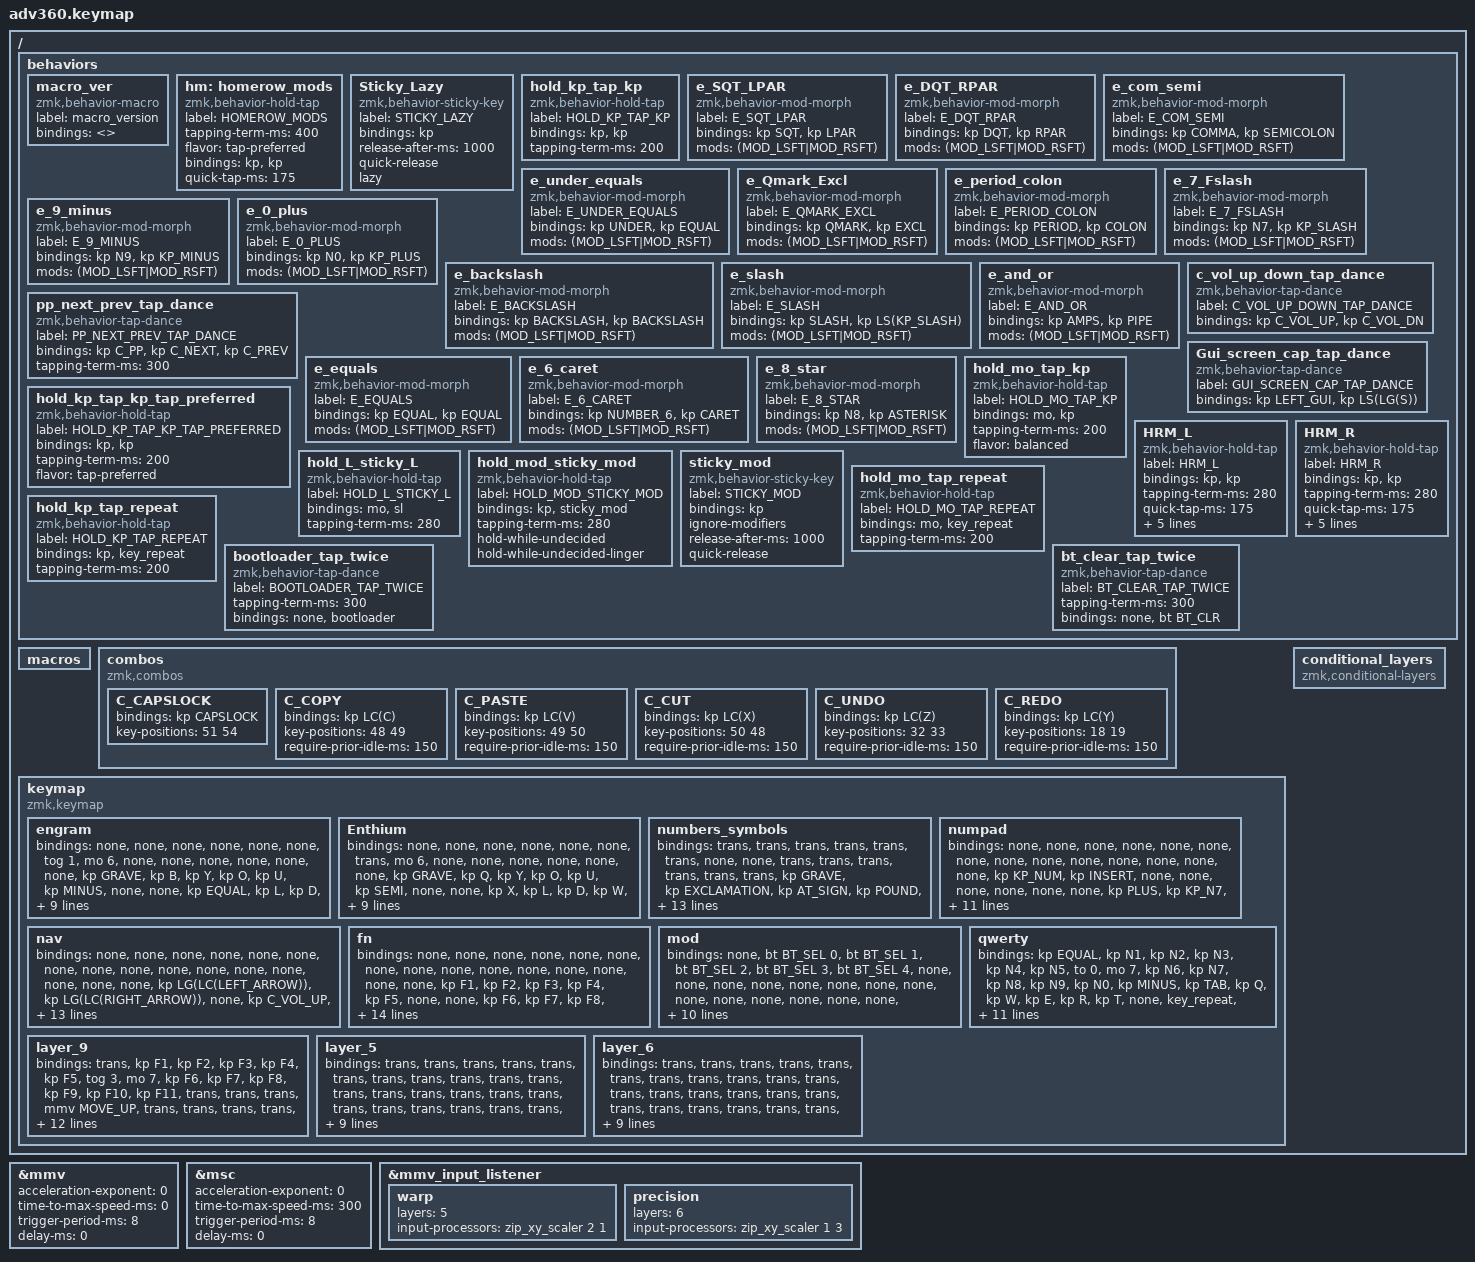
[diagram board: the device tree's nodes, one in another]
#define ZMK_POINTING_DEFAULT_MOVE_VAL 1800  // default: 600
#define ZMK_POINTING_DEFAULT_SCRL_VAL 20    // default: 10

#include <dt-bindings/zmk/stp.h>
#include <input/processors.dtsi>
#include <behaviors.dtsi>
#include <dt-bindings/zmk/backlight.h>
#include <dt-bindings/zmk/bt.h>
#include <dt-bindings/zmk/keys.h>
#include <dt-bindings/zmk/pointing.h>
#include <dt-bindings/zmk/rgb.h>

&mmv {
    acceleration-exponent = <0>;
    time-to-max-speed-ms = <0>;
    trigger-period-ms = <8>;
    delay-ms = <0>;
};

&msc {
    acceleration-exponent = <0>;
    time-to-max-speed-ms = <300>;
    trigger-period-ms = <8>;
    delay-ms = <0>;
};

&mmv_input_listener {
    warp {
        layers = <5>;
        input-processors = <&zip_xy_scaler 2 1>;
    };

    precision {
        layers = <6>;
        input-processors = <&zip_xy_scaler 1 3>;
    };
};

/ {
    behaviors {
        #include "macros.dtsi"
      #include "version.dtsi"
      #ifndef VERSION_MACRO

        macro_ver: macro_ver {
            compatible = "zmk,behavior-macro";
            label = "macro_version";
            #binding-cells = <0>;
            bindings = <>;
        };

        #endif

        hm: homerow_mods {
            compatible = "zmk,behavior-hold-tap";
            label = "HOMEROW_MODS";
            #binding-cells = <2>;
            tapping-term-ms = <400>;
            flavor = "tap-preferred";
            bindings = <&kp>, <&kp>;

            quick-tap-ms = <175>;
        };

        Sticky_Lazy: Sticky_Lazy {
            compatible = "zmk,behavior-sticky-key";
            label = "STICKY_LAZY";
            bindings = <&kp>;
            #binding-cells = <1>;
            release-after-ms = <1000>;
            quick-release;
            lazy;
        };

        hold_kp_tap_kp: hold_kp_tap_kp {
            compatible = "zmk,behavior-hold-tap";
            label = "HOLD_KP_TAP_KP";
            bindings = <&kp>, <&kp>;

            #binding-cells = <2>;
            tapping-term-ms = <200>;
        };

        e_SQT_LPAR: e_SQT_LPAR {
            compatible = "zmk,behavior-mod-morph";
            label = "E_SQT_LPAR";
            bindings = <&kp SQT>, <&kp LPAR>;

            #binding-cells = <0>;
            mods = <(MOD_LSFT|MOD_RSFT)>;
        };

        e_DQT_RPAR: e_DQT_RPAR {
            compatible = "zmk,behavior-mod-morph";
            label = "E_DQT_RPAR";
            bindings = <&kp DQT>, <&kp RPAR>;

            #binding-cells = <0>;
            mods = <(MOD_LSFT|MOD_RSFT)>;
        };

        e_com_semi: e_com_semi {
            compatible = "zmk,behavior-mod-morph";
            label = "E_COM_SEMI";
            bindings = <&kp COMMA>, <&kp SEMICOLON>;

            #binding-cells = <0>;
            mods = <(MOD_LSFT|MOD_RSFT)>;
        };

        e_under_equals: e_under_equals {
            compatible = "zmk,behavior-mod-morph";
            label = "E_UNDER_EQUALS";
            bindings = <&kp UNDER>, <&kp EQUAL>;

            #binding-cells = <0>;
            mods = <(MOD_LSFT|MOD_RSFT)>;
        };

        e_Qmark_Excl: e_Qmark_Excl {
            compatible = "zmk,behavior-mod-morph";
            label = "E_QMARK_EXCL";
            bindings = <&kp QMARK>, <&kp EXCL>;

            #binding-cells = <0>;
            mods = <(MOD_LSFT|MOD_RSFT)>;
        };

        e_period_colon: e_period_colon {
            compatible = "zmk,behavior-mod-morph";
            label = "E_PERIOD_COLON";
            bindings = <&kp PERIOD>, <&kp COLON>;

            #binding-cells = <0>;
            mods = <(MOD_LSFT|MOD_RSFT)>;
        };

        e_7_Fslash: e_7_Fslash {
            compatible = "zmk,behavior-mod-morph";
            label = "E_7_FSLASH";
            bindings = <&kp N7>, <&kp KP_SLASH>;

            #binding-cells = <0>;
            mods = <(MOD_LSFT|MOD_RSFT)>;
        };

        e_9_minus: e_9_minus {
            compatible = "zmk,behavior-mod-morph";
            label = "E_9_MINUS";
            bindings = <&kp N9>, <&kp KP_MINUS>;

            #binding-cells = <0>;
            mods = <(MOD_LSFT|MOD_RSFT)>;
        };

        e_0_plus: e_0_plus {
            compatible = "zmk,behavior-mod-morph";
            label = "E_0_PLUS";
            bindings = <&kp N0>, <&kp KP_PLUS>;

            #binding-cells = <0>;
            mods = <(MOD_LSFT|MOD_RSFT)>;
        };

        e_backslash: e_backslash {
            compatible = "zmk,behavior-mod-morph";
            label = "E_BACKSLASH";
            bindings = <&kp BACKSLASH>, <&kp BACKSLASH>;

            #binding-cells = <0>;
            mods = <(MOD_LSFT|MOD_RSFT)>;
        };

        e_slash: e_slash {
            compatible = "zmk,behavior-mod-morph";
            label = "E_SLASH";
            bindings = <&kp SLASH>, <&kp LS(KP_SLASH)>;

            #binding-cells = <0>;
            mods = <(MOD_LSFT|MOD_RSFT)>;
        };

        e_and_or: e_and_or {
            compatible = "zmk,behavior-mod-morph";
            label = "E_AND_OR";
            bindings = <&kp AMPS>, <&kp PIPE>;

            #binding-cells = <0>;
            mods = <(MOD_LSFT|MOD_RSFT)>;
        };

        pp_next_prev_tap_dance: pp_next_prev_tap_dance {
            compatible = "zmk,behavior-tap-dance";
            label = "PP_NEXT_PREV_TAP_DANCE";
            #binding-cells = <0>;
            bindings = <&kp C_PP>, <&kp C_NEXT>, <&kp C_PREV>;

            tapping-term-ms = <300>;
        };

        c_vol_up_down_tap_dance: c_vol_up_down_tap_dance {
            compatible = "zmk,behavior-tap-dance";
            label = "C_VOL_UP_DOWN_TAP_DANCE";
            #binding-cells = <0>;
            bindings = <&kp C_VOL_UP>, <&kp C_VOL_DN>;
        };

        Gui_screen_cap_tap_dance: Gui_screen_cap_tap_dance {
            compatible = "zmk,behavior-tap-dance";
            label = "GUI_SCREEN_CAP_TAP_DANCE";
            #binding-cells = <0>;
            bindings = <&kp LEFT_GUI>, <&kp LS(LG(S))>;
        };

        e_equals: e_equals {
            compatible = "zmk,behavior-mod-morph";
            label = "E_EQUALS";
            bindings = <&kp EQUAL>, <&kp EQUAL>;

            #binding-cells = <0>;
            mods = <(MOD_LSFT|MOD_RSFT)>;
        };

        e_6_caret: e_6_caret {
            compatible = "zmk,behavior-mod-morph";
            label = "E_6_CARET";
            bindings = <&kp NUMBER_6>, <&kp CARET>;

            #binding-cells = <0>;
            mods = <(MOD_LSFT|MOD_RSFT)>;
        };

        e_8_star: e_8_star {
            compatible = "zmk,behavior-mod-morph";
            label = "E_8_STAR";
            bindings = <&kp N8>, <&kp ASTERISK>;

            #binding-cells = <0>;
            mods = <(MOD_LSFT|MOD_RSFT)>;
        };

        hold_mo_tap_kp: hold_mo_tap_kp {
            compatible = "zmk,behavior-hold-tap";
            label = "HOLD_MO_TAP_KP";
            bindings = <&mo>, <&kp>;

            #binding-cells = <2>;
            tapping-term-ms = <200>;
            flavor = "balanced";
        };

        hold_kp_tap_kp_tap_preferred: hold_kp_tap_kp_tap_preferred {
            compatible = "zmk,behavior-hold-tap";
            label = "HOLD_KP_TAP_KP_TAP_PREFERRED";
            bindings = <&kp>, <&kp>;

            #binding-cells = <2>;
            tapping-term-ms = <200>;
            flavor = "tap-preferred";
        };

        HRM_L: HRM_L {
            compatible = "zmk,behavior-hold-tap";
            label = "HRM_L";
            bindings = <&kp>, <&kp>;

            #binding-cells = <2>;
            tapping-term-ms = <280>;
            quick-tap-ms = <175>;
            require-prior-idle-ms = <150>;
            flavor = "balanced";
            hold-trigger-key-positions = <7 8 9 10 11 12 13 21 22 23 24 25 26 27 38 39 40 41 42 43 44 45 54 55 56 57 58 59 69 70 71 72 73 74 75 35 36 37 38 52 53 65 66 67 68 69 70>;
            hold-trigger-on-release;
        };

        HRM_R: HRM_R {
            compatible = "zmk,behavior-hold-tap";
            label = "HRM_R";
            bindings = <&kp>, <&kp>;

            #binding-cells = <2>;
            tapping-term-ms = <280>;
            quick-tap-ms = <175>;
            require-prior-idle-ms = <150>;
            flavor = "balanced";
            hold-trigger-on-release;
            hold-trigger-key-positions = <0 1 2 3 4 5 6 14 15 16 17 18 19 20 28 29 30 31 32 33 34 35 36 46 47 48 49 50 51 52 60 61 62 63 64 65 66 67 36 37 38 53 68 69 70>;
        };

        hold_L_sticky_L: hold_L_sticky_L {
            compatible = "zmk,behavior-hold-tap";
            label = "HOLD_L_STICKY_L";
            bindings = <&mo>, <&sl>;

            #binding-cells = <2>;
            tapping-term-ms = <280>;
        };

        hold_mod_sticky_mod: hold_mod_sticky_mod {
            compatible = "zmk,behavior-hold-tap";
            label = "HOLD_MOD_STICKY_MOD";
            bindings = <&kp>, <&sticky_mod>;

            #binding-cells = <2>;
            tapping-term-ms = <280>;
            hold-while-undecided;
            hold-while-undecided-linger;
        };

        sticky_mod: sticky_mod {
            compatible = "zmk,behavior-sticky-key";
            label = "STICKY_MOD";
            bindings = <&kp>;
            #binding-cells = <1>;
            ignore-modifiers;
            release-after-ms = <1000>;
            quick-release;
        };

        hold_mo_tap_repeat: hold_mo_tap_repeat {
            compatible = "zmk,behavior-hold-tap";
            label = "HOLD_MO_TAP_REPEAT";
            bindings = <&mo>, <&key_repeat>;

            #binding-cells = <2>;
            tapping-term-ms = <200>;
        };

        hold_kp_tap_repeat: hold_kp_tap_repeat {
            compatible = "zmk,behavior-hold-tap";
            label = "HOLD_KP_TAP_REPEAT";
            bindings = <&kp>, <&key_repeat>;

            #binding-cells = <2>;
            tapping-term-ms = <200>;
        };

        bootloader_tap_twice: bootloader_tap_twice {
            compatible = "zmk,behavior-tap-dance";
            label = "BOOTLOADER_TAP_TWICE";
            #binding-cells = <0>;
            tapping-term-ms = <300>;
            bindings = <&none>, <&bootloader>;
        };

        bt_clear_tap_twice: bt_clear_tap_twice {
            compatible = "zmk,behavior-tap-dance";
            label = "BT_CLEAR_TAP_TWICE";
            #binding-cells = <0>;
            tapping-term-ms = <300>;
            bindings = <&none>, <&bt BT_CLR>;
        };
    };

    macros {
    };

    combos {
        compatible = "zmk,combos";

        C_CAPSLOCK {
            bindings = <&kp CAPSLOCK>;
            key-positions = <51 54>;
        };

        C_COPY {
            bindings = <&kp LC(C)>;
            key-positions = <48 49>;
            require-prior-idle-ms = <150>;
        };

        C_PASTE {
            bindings = <&kp LC(V)>;
            key-positions = <49 50>;
            require-prior-idle-ms = <150>;
        };

        C_CUT {
            bindings = <&kp LC(X)>;
            key-positions = <50 48>;
            require-prior-idle-ms = <150>;
        };

        C_UNDO {
            bindings = <&kp LC(Z)>;
            key-positions = <32 33>;
            require-prior-idle-ms = <150>;
        };

        C_REDO {
            bindings = <&kp LC(Y)>;
            key-positions = <18 19>;
            require-prior-idle-ms = <150>;
        };
    };

    keymap {
        compatible = "zmk,keymap";

        engram {
            bindings = <
&none                   &none  &none  &none  &none  &none      &tog 1                                  &mo 6      &none      &none  &none  &none  &none  &none
&kp GRAVE               &kp B  &kp Y  &kp O  &kp U  &kp MINUS  &none                                   &none      &kp EQUAL  &kp L  &kp D  &kp W  &kp V  &kp Z
&caps_word              &kp C  &kp I  &kp E  &kp A  &kp SEMI   &none   &none  &none      &none  &none  &none      &kp SQT    &kp H  &kp T  &kp S  &kp N  &kp Q
&sticky_mod LEFT_SHIFT  &kp G  &kp X  &kp J  &kp K  &kp COMMA                 &none      &none                    &kp DOT    &kp R  &kp M  &kp F  &kp P  &sticky_mod LEFT_SHIFT
&none                   &none  &none  &none  &mo 3             &mo 4   &sl 2  &none      &none  &sl 2  &kp SPACE             &mo 5  &none  &none  &none  &none
            >;
        };

        Enthium {
            bindings = <
&none                   &none    &none      &none      &none      &none     &trans                                  &mo 6      &none  &none  &none  &none  &none  &none
&kp GRAVE               &kp Q    &kp Y      &kp O      &kp U      &kp SEMI  &none                                   &none      &kp X  &kp L  &kp D  &kp W  &kp Z  &kp BSLH
&kp B                   &kp C    &kp I      &kp E      &kp A      &kp DOT   &none   &none  &none      &none  &none  &none      &kp K  &kp H  &kp T  &kp N  &kp S  &kp V
&sticky_mod LEFT_SHIFT  &kp SQT  &kp MINUS  &kp EQUAL  &kp COMMA  &kp FSLH                 &none      &none                    &kp J  &kp M  &kp G  &kp P  &kp F  &sticky_mod LEFT_SHIFT
&none                   &none    &none      &none      &mo 3                &kp R   &mo 4  &none      &none  &sl 2  &kp SPACE         &mo 5  &none  &none  &none  &none
            >;
        };

        numbers_symbols {
            bindings = <
&trans     &trans           &trans       &trans        &trans        &trans        &none                                       &none   &trans        &trans         &trans        &trans                &trans                 &trans
&kp GRAVE  &kp EXCLAMATION  &kp AT_SIGN  &kp POUND     &kp DOLLAR    &kp PERCENT   &trans                                      &trans  &kp CARET     &kp AMPERSAND  &kp ASTERISK  &kp LEFT_PARENTHESIS  &kp RIGHT_PARENTHESIS  &kp BSLH
&trans     &kp N1           &kp N2       &kp NUMBER_3  &kp NUMBER_4  &kp NUMBER_5  &trans  &trans  &trans      &trans  &trans  &trans  &kp NUMBER_6  &kp NUMBER_7   &kp NUMBER_8  &kp NUMBER_9          &kp NUMBER_0           &kp FSLH
&trans     &none            &none        &none         &none         &kp COMMA                     &trans      &trans                  &kp DOT       &kp MINUS      &kp EQUAL     &kp LBKT              &kp RBKT               &trans
&trans     &trans           &trans       &trans        &mo 3                       &mo 4   &trans  &trans      &trans  &trans  &trans                &mo 5          &trans        &trans                &trans                 &trans
            >;
        };

        numpad {
            bindings = <
&none       &none                 &none                 &none                   &none                     &none  &none                                    &none   &none         &none      &none      &none      &none            &none
&kp KP_NUM  &kp INSERT            &none                 &none                   &none                     &none  &none                                    &none   &kp PLUS      &kp KP_N7  &kp KP_N8  &kp KP_N9  &kp KP_MULTIPLY  &none
&trans      &sticky_mod LEFT_GUI  &sticky_mod LEFT_ALT  &sticky_mod LEFT_SHIFT  &sticky_mod LEFT_CONTROL  &none  &none  &none   &none      &none  &none   &none   &kp KP_MINUS  &kp KP_N4  &kp KP_N5  &kp KP_N6  &kp KP_SLASH     &none
&trans      &none                 &none                 &none                   &none                     &none                 &none      &none                  &kp PERIOD    &kp KP_N1  &kp KP_N2  &kp KP_N3  &kp ENTER        &trans
&none       &none                 &none                 &none                   &trans                           &mo 4  &trans  &none      &none  &trans  &trans                &kp KP_N0  &none      &none      &none            &none
            >;
        };

        nav {
            bindings = <
&none   &none                 &none                   &none                    &none                     &none                    &none                                     &none   &none           &none      &none      &none       &none              &none
&none   &none                 &kp LG(LC(LEFT_ARROW))  &kp LG(LC(RIGHT_ARROW))  &none                     &kp C_VOL_UP             &none                                     &none   &none           &kp ENTER  &kp BSPC   &kp DELETE  &kp LC(BACKSPACE)  &none
&trans  &sticky_mod LEFT_GUI  &sticky_mod LEFT_ALT    &sticky_mod LEFT_SHIFT   &sticky_mod LEFT_CONTROL  &kp C_VOL_DN             &none   &none   &none      &none  &none   &none   &msc SCRL_UP    &kp LEFT   &kp DOWN   &kp UP      &kp RIGHT          &none
&trans  &kp ESC               &mkp MB4                &mkp MB5                 &kp TAB                   &pp_next_prev_tap_dance                  &none      &none                  &msc SCRL_DOWN  &kp HOME   &kp PG_DN  &kp PG_UP   &kp END            &trans
&none   &none                 &none                   &none                    &trans                                             &trans  &trans  &none      &none  &trans  &trans                  &mo 5      &none      &none       &none              &none
            >;
        };

        fn {
            bindings = <
&none                  &none                 &none                 &none                   &none                     &none         &none                                     &none   &none    &none                     &none                   &none                 &none                 &none
&none                  &kp F1                &kp F2                &kp F3                  &kp F4                    &kp F5        &none                                     &none   &kp F6   &kp F7                    &kp F8                  &kp F9                &kp F10               &kp F11
&bootloader_tap_twice  &sticky_mod LEFT_GUI  &sticky_mod LEFT_ALT  &sticky_mod LEFT_SHIFT  &sticky_mod LEFT_CONTROL  &kp F11       &none   &none   &none      &none  &none   &none   &kp F12  &sticky_mod LEFT_CONTROL  &sticky_mod LEFT_SHIFT  &sticky_mod LEFT_ALT  &sticky_mod LEFT_GUI  &bootloader_tap_twice
&bt_clear_tap_twice    &bt BT_SEL 0          &bt BT_SEL 1          &bt BT_SEL 2            &bt BT_SEL 3              &bt BT_SEL 4                  &none      &none                  &none    &none                     &none                   &none                 &none                 &none
&none                  &none                 &none                 &none                   &trans                                  &trans  &trans  &none      &none  &trans  &trans           &trans                    &none                   &none                 &none                 &none
            >;
        };

        mod {
            bindings = <
&none  &bt BT_SEL 0  &bt BT_SEL 1  &bt BT_SEL 2  &bt BT_SEL 3  &bt BT_SEL 4  &none                                                  &none                   &none  &none       &none       &none  &none  &none
&none  &none         &none         &none         &none         &none         &bootloader                                            &bootloader             &none  &none       &none       &none  &none  &none
&none  &none         &none         &none         &none         &none         &trans       &none  &none      &bt BT_CLR  &none       &rgb_ug RGB_MEFS_CMD 5  &none  &none       &none       &none  &none  &none
&none  &none         &none         &none         &macro_ver    &none                             &none      &none                                           &none  &none       &none       &none  &none  &none
&none  &none         &none         &none         &none                       &none        &none  &none      &none       &bl BL_TOG  &rgb_ug RGB_TOG                &bl BL_INC  &bl BL_DEC  &none  &none  &none
            >;
        };

        qwerty {
            bindings = <
&kp EQUAL  &kp N1     &kp N2  &kp N3    &kp N4     &kp N5  &to 0                                                                 &mo 7        &kp N6  &kp N7  &kp N8     &kp N9    &kp N0    &kp MINUS
&kp TAB    &kp Q      &kp W   &kp E     &kp R      &kp T   &none                                                                 &key_repeat  &kp Y   &kp U   &kp I      &kp O     &kp P     &kp BSLH
&kp ESC    &kp A      &kp S   &kp D     &kp F      &kp G   &none           &kp LEFT_CONTROL  &kp LALT      &kp LGUI   &kp RCTRL  &kp CAPS     &kp H   &kp J   &kp K      &kp L     &kp SEMI  &kp SQT
&kp DEL    &kp Z      &kp X   &kp C     &kp V      &kp B                                     &kp HOME      &kp PG_UP                          &kp N   &kp M   &kp COMMA  &kp DOT   &kp FSLH  &kp BACKSPACE
&mo 6      &kp GRAVE  &mo 3   &kp LEFT  &kp RIGHT          &kp LEFT_SHIFT  &mo 3             &kp END       &kp PG_DN  &kp ENTER  &kp SPACE            &kp UP  &kp DOWN   &kp LBKT  &kp RBKT  &mo 6
            >;
        };

        layer_9 {
            bindings = <
&trans  &kp F1  &kp F2          &kp F3          &kp F4           &kp F5  &tog 3                                      &mo 7   &kp F6  &kp F7          &kp F8          &kp F9           &kp F10  &kp F11
&trans  &trans  &trans          &mmv MOVE_UP    &trans           &trans  &trans                                      &trans  &trans  &msc SCRL_UP    &mmv MOVE_UP    &msc SCRL_DOWN   &trans   &kp F12
&trans  &trans  &mmv MOVE_LEFT  &mmv MOVE_DOWN  &mmv MOVE_RIGHT  &trans  &trans  &trans  &trans      &trans  &trans  &trans  &trans  &mmv MOVE_LEFT  &mmv MOVE_DOWN  &mmv MOVE_RIGHT  &trans   &trans
&trans  &trans  &trans          &trans          &trans           &trans                  &trans      &trans                  &trans  &mkp LCLK       &mkp MCLK       &mkp RCLK        &trans   &trans
&trans  &trans  &trans          &kp HOME        &kp END                  &mo 9   &mo 10  &trans      &trans  &mo 9   &mo 10          &kp PAGE_UP     &kp PAGE_DOWN   &trans           &trans   &trans
            >;
        };

        layer_5 {
            bindings = <
&trans  &trans  &trans  &trans  &trans  &trans  &trans                                      &trans  &trans  &trans  &trans  &trans  &trans  &trans
&trans  &trans  &trans  &trans  &trans  &trans  &trans                                      &trans  &trans  &trans  &trans  &trans  &trans  &trans
&trans  &trans  &trans  &trans  &trans  &trans  &trans  &trans  &trans      &trans  &trans  &trans  &trans  &trans  &trans  &trans  &trans  &trans
&trans  &trans  &trans  &trans  &trans  &trans                  &trans      &trans                  &trans  &trans  &trans  &trans  &trans  &trans
&trans  &trans  &trans  &trans  &trans          &trans  &trans  &trans      &trans  &trans  &trans          &trans  &trans  &trans  &trans  &trans
            >;
        };

        layer_6 {
            bindings = <
&trans  &trans  &trans  &trans  &trans  &trans  &trans                                      &trans  &trans  &trans  &trans  &trans  &trans  &trans
&trans  &trans  &trans  &trans  &trans  &trans  &trans                                      &trans  &trans  &trans  &trans  &trans  &trans  &trans
&trans  &trans  &trans  &trans  &trans  &trans  &trans  &trans  &trans      &trans  &trans  &trans  &trans  &trans  &trans  &trans  &trans  &trans
&trans  &trans  &trans  &trans  &trans  &trans                  &trans      &trans                  &trans  &trans  &trans  &trans  &trans  &trans
&trans  &trans  &trans  &trans  &trans          &trans  &trans  &trans      &trans  &trans  &trans          &trans  &trans  &trans  &trans  &trans
            >;
        };
    };

    conditional_layers { compatible = "zmk,conditional-layers"; };
};
